# PRM_MPU register map
Vendor: Texas Instruments
Peripheral module from a debugger description file (folder am335x).
Registers are 32-bit, access per field, no defined reset value unless marked. A register's access mark holds for its fields unless they carry their own. Offsets are as the file gives them; lines under a group give offsets from that group; [hi:lo] are bit positions; {n}, {i} and the like mark numbered series; 'fields as' and 'values as' point back to an identical list; <NAME> marks a mode.

## PRM_MPU
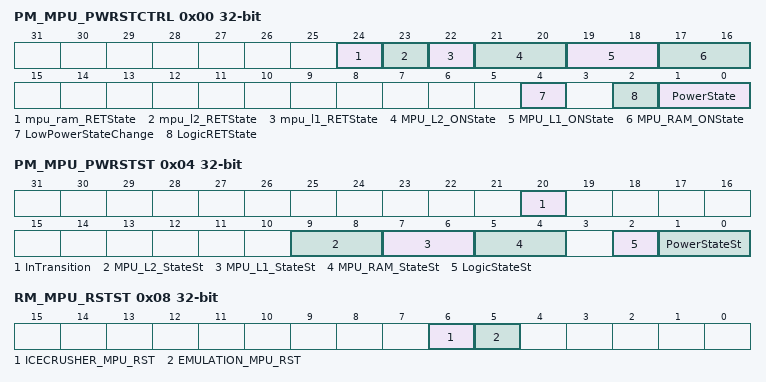
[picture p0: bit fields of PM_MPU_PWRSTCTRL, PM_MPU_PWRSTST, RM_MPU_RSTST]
0x00 PM_MPU_PWRSTCTRL — This register controls the MPU power state to reach upon mpu domain sleep transition
  [24] mpu_ram_RETState rw — Default power domain memory(ram) retention state when power domain is in retention
  [23] mpu_l2_RETState rw — Default power domain memory(L2) retention state when power domain is in retention
  [22] mpu_l1_RETState rw — Default power domain memory(L1) retention state when power domain is in retention
  [21:20] MPU_L2_ONState ro — Default power domain memory state when domain is ON.
    3=Mem_on (Memory bank is on when the domain is ON.)
  [19:18] MPU_L1_ONState ro — Default power domain memory state when domain is ON.
    3=Mem_on (Memory bank is on when the domain is ON.)
  [17:16] MPU_RAM_ONState rw — Default power domain memory state when domain is ON.
    0=Mem_off; 3=Mem_on (Memory bank is on when the domain is ON.)
  [4] LowPowerStateChange rw — Power state change request when domain has already performed a sleep transition. Allows going into deeper low power state without waking up the power domain.
    0=DIS (Do not request a low power state change.); 1=EN (Request a low power state change. This bit is automatically cleared when the power state is effectively changed or when power state is ON.)
  [2] LogicRETState rw — Logic state when power domain is RETENTION
    0=logic_off (Only retention registers are retained and remaing logic is off when the domain is in RETENTION state.); 1=logic_ret (Whole logic is retained when domain is in RETENTION state.)
  [1:0] PowerState rw — Power state control
    0=OFF (OFF State); 1=RET; 3=ON (ON State)
0x04 PM_MPU_PWRSTST ro — This register provides a status on the current MPU power domain state0. [warm reset insensitive]
  [20] InTransition — Domain transition status
    0=No (No on-going transition on power domain); 1=Ongoing (Power domain transition is in progress.)
  [9:8] MPU_L2_StateSt — MPU L2 memory state status
    0=Mem_off (Memory is OFF); 3=Mem_on (Memory is ON)
  [7:6] MPU_L1_StateSt — MPU L1 memory state status
    0=Mem_off (Memory is OFF); 3=Mem_on (Memory is ON)
  [5:4] MPU_RAM_StateSt — MPU_RAM memory state status
    0=Mem_off (Memory is OFF); 3=Mem_on (Memory is ON)
  [2] LogicStateSt — Logic state status
    0=OFF (Logic in domain is OFF); 1=ON (Logic in domain is ON)
  [1:0] PowerStateSt — Current Power State Status
    0=OFF (OFF State [warm reset insensitive]); 1=RET (RET State); 3=ON (ON State [warm reset insensitive])
0x08 RM_MPU_RSTST — This register logs the different reset sources of the ALWON domain. Each bit is set upon release of the domain reset signal. Must be cleared by software. [warm reset insensitive]
  [6] ICECRUSHER_MPU_RST rw — MPU Processor has been reset due to MPU ICECRUSHER1 reset event
    0=RESET_NO (No icecrusher reset); 1=RESET_YES (MPU Processor has been reset upon icecursher reset)
  [5] EMULATION_MPU_RST rw — MPU Processor has been reset due to emulation reset source e.g. assert reset command initiated by the icepick module
    0=RESET_NO (No emulation reset); 1=RESET_YES (MPU Processor has been reset upon emulation reset)
